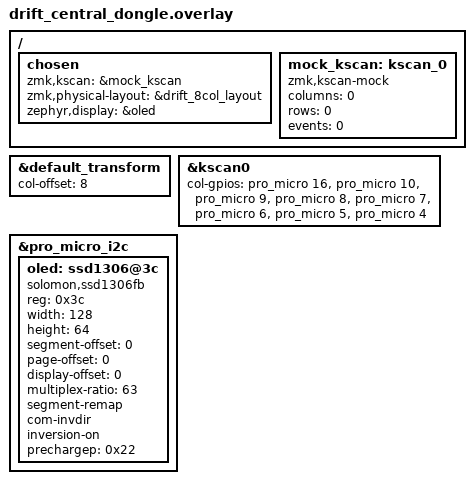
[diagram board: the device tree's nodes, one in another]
// Copyright (c) 2025 The ZMK Contributors
// SPDX-License-Identifier: MIT
 
#include "drift.dtsi"
#include <dt-bindings/zmk/matrix_transform.h>

&default_transform {
    col-offset = <8>;
};

&kscan0 {
    col-gpios
        = <&pro_micro 16 GPIO_ACTIVE_HIGH>
        , <&pro_micro 10 GPIO_ACTIVE_HIGH>
        , <&pro_micro 9 GPIO_ACTIVE_HIGH>
        , <&pro_micro 8 GPIO_ACTIVE_HIGH>
        , <&pro_micro 7 GPIO_ACTIVE_HIGH>
        , <&pro_micro 6 GPIO_ACTIVE_HIGH>
		, <&pro_micro 5 GPIO_ACTIVE_HIGH>
        , <&pro_micro 4 GPIO_ACTIVE_HIGH>
        ;
};

/ {	
	chosen {
        zmk,kscan = &mock_kscan;
        zmk,physical-layout = &drift_8col_layout;
        zephyr,display = &oled;
    };
		
    mock_kscan: kscan_0 {
        compatible = "zmk,kscan-mock";
        columns = <0>;
        rows = <0>;
        events = <0>;
    };	
};

&pro_micro_i2c {
    status = "okay";
    oled: ssd1306@3c {
        compatible = "solomon,ssd1306fb";
        reg = <0x3c>;
        width = <128>;
        height = <64>;
        segment-offset = <0>;
        page-offset = <0>;
        display-offset = <0>;
        multiplex-ratio = <63>;

        // Responsible for oled invert
        segment-remap;
        com-invdir;
        
        //com-sequential;
        inversion-on;
        prechargep = <0x22>;
    };
};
